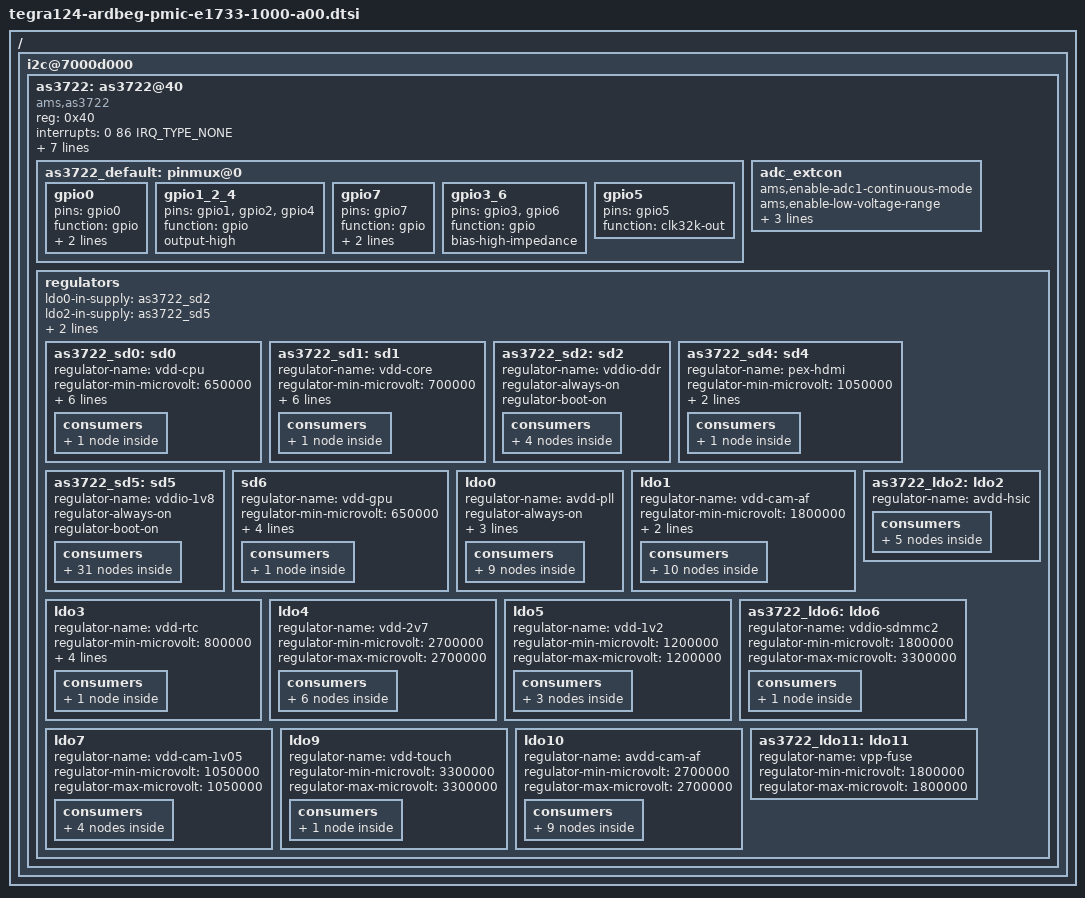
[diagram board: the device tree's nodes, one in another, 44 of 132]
/*
 * arch/arm/boot/dts/tegra124-platforms/tegra124-ardbeg-pmic-e1733-1000-a00.dtsi
 *
 * Copyright (c) 2014, NVIDIA CORPORATION.  All rights reserved.
 *
 * This program is free software; you can redistribute it and/or modify
 * it under the terms of the GNU General Public License as published by
 * the Free Software Foundation; either version 2 of the License, or
 * (at your option) any later version.
 *
 * This program is distributed in the hope that it will be useful, but WITHOUT
 * ANY WARRANTY; without even the implied warranty of MERCHANTABILITY or
 * FITNESS FOR A PARTICULAR PURPOSE.  See the GNU General Public License for
 * more details.
 *
 * You should have received a copy of the GNU General Public License along
 * with this program; if not, write to the Free Software Foundation, Inc.,
 * 51 Franklin Street, Fifth Floor, Boston, MA  02110-1301, USA.
 */

 #include <dt-bindings/gpio/tegra-gpio.h>
 #include <dt-bindings/mfd/as3722.h>
 #include <dt-bindings/regulator/regulator.h>

/ {
	i2c@7000d000 {
		as3722: as3722@40 {
			compatible = "ams,as3722";
			reg = <0x40>;
			interrupts = <0 86 IRQ_TYPE_NONE>;

			#interrupt-cells = <2>;
			interrupt-controller;

			gpio-controller;
			#gpio-cells = <2>;

			ams,major-rev = <1>;
			ams,minor-rev = <2>;
			ams,system-power-controller;
			ams,enable-clock32k-out;

			pinctrl-names = "default";
			pinctrl-0 = <&as3722_default>;

			as3722_default: pinmux@0 {
				gpio0 {
					pins = "gpio0";
					function = "gpio";
					bias-pull-down;
					output-low;
				};

				gpio1_2_4 {
					pins = "gpio1", "gpio2", "gpio4";
					function = "gpio";
					output-high;
				};

				gpio7 {
					pins = "gpio7";
					function = "gpio";
					bias-pull-up;
					output-low;
				};

				gpio3_6 {
					pins = "gpio3", "gpio6";
					function = "gpio";
					bias-high-impedance;
				};

				gpio5 {
					pins = "gpio5";
					function = "clk32k-out";
				};
			};

			adc_extcon: adc_extcon {
				ams,enable-adc1-continuous-mode;
				ams,enable-low-voltage-range;
				ams,adc-channel = <12>;
				ams,hi-threshold = <0x100>;
				ams,low-threshold = <0x80>;
				#extcon-cells = <1>;
				#io-channel-cells = <1>;
			};

			regulators {
				ldo0-in-supply = <&as3722_sd2>;
				ldo2-in-supply = <&as3722_sd5>;
				ldo5-in-supply = <&as3722_sd5>;
				ldo7-in-supply = <&as3722_sd5>;

				as3722_sd0: sd0 {
					regulator-name = "vdd-cpu";
					regulator-min-microvolt = <650000>;
					regulator-max-microvolt = <1400000>;
					regulator-max-microamp = <3500000>;
					regulator-always-on;
					regulator-boot-on;
					ams,ext-control = <AS3722_EXT_CONTROL_PIN_ENABLE2>;
					consumers {
						c1 {
							regulator-consumer-supply = "vdd_cpu";
						};
					};
				};

				as3722_sd1: sd1 {
					regulator-name = "vdd-core";
					regulator-min-microvolt = <700000>;
					regulator-max-microvolt = <1400000>;
					regulator-max-microamp = <3500000>;
					regulator-always-on;
					regulator-boot-on;
					ams,ext-control = <AS3722_EXT_CONTROL_PIN_ENABLE1>;

					consumers {
						c0 {
							regulator-consumer-supply = "vdd_core";
						};
					};
				};

				as3722_sd2: sd2 {
					regulator-name = "vddio-ddr";
					regulator-always-on;
					regulator-boot-on;

					consumers {
						c0 {
							regulator-consumer-supply = "vddio_ddr";
						};
						c1 {
							regulator-consumer-supply = "vddio_ddr_mclk";
						};
						c2 {
							regulator-consumer-supply = "vddio_ddr3";
						};
						c3 {
							regulator-consumer-supply = "vcore1_ddr3";
						};
					};
				};

				as3722_sd4: sd4 {
					regulator-name = "pex-hdmi";
					regulator-min-microvolt = <1050000>;
				        regulator-max-microvolt = <1050000>;
					regulator-boot-on;

					consumers {
						c6 {
							regulator-consumer-supply = "vddio_pex_sata";
							regulator-consumer-device = "tegra-sata.0";
						};
					};
				};

				as3722_sd5: sd5 {
					regulator-name = "vddio-1v8";
					regulator-always-on;
					regulator-boot-on;

					consumers {
						c0 {
							regulator-consumer-supply = "dbvdd";
							regulator-consumer-device = "tegra-snd-rt5639.0";
						};
						c1 {
							regulator-consumer-supply = "dbvdd";
							regulator-consumer-device = "tegra-snd-rt5645.0";
						};
						c2 {
							regulator-consumer-supply = "avdd";
							regulator-consumer-device = "tegra-snd-rt5639.0";
						};
						c3 {
							regulator-consumer-supply = "avdd";
							regulator-consumer-device = "tegra-snd-rt5645.0";
						};
						c4 {
							regulator-consumer-supply = "dmicvdd";
							regulator-consumer-device = "tegra-snd-rt5639.0";
						};
						c5 {
							regulator-consumer-supply = "dmicvdd";
							regulator-consumer-device = "tegra-snd-rt5645.0";
						};
						c6 {
							regulator-consumer-supply = "avdd_osc";
						};
						c7 {
							regulator-consumer-supply = "vddio_sys";
						};
						c8 {
							regulator-consumer-supply = "vddio_sys_2";
						};
						c9 {
							regulator-consumer-supply = "vddio_gmi";
						};
						c11 {
							regulator-consumer-supply = "vddio_sdmmc";
							regulator-consumer-device = "sdhci-tegra.0";
						};
						c13 {
							regulator-consumer-supply = "vddio_sdmmc";
							regulator-consumer-device = "sdhci-tegra.3";
						};
						c15 {
							regulator-consumer-supply = "avdd_pll_utmip";
							regulator-consumer-device = "tegra-udc.0";
						};
						c16 {
							regulator-consumer-supply = "avdd_pll_utmip";
							regulator-consumer-device = "tegra-ehci.0";
						};
						c17 {
							regulator-consumer-supply = "avdd_pll_utmip";
							regulator-consumer-device = "tegra-ehci.1";
						};
						c18 {
							regulator-consumer-supply = "avdd_pll_utmip";
							regulator-consumer-device = "tegra-ehci.2";
						};
						c20 {
							regulator-consumer-supply = "vddio_audio";
						};
						c22 {
							regulator-consumer-supply = "vddio_uart";
						};
						c24 {
							regulator-consumer-supply = "vddio_bb";
						};
						c26 {
							regulator-consumer-supply = "vdd_1v8b";
							regulator-consumer-device = "0-0048";
						};
						c27 {
							regulator-consumer-supply = "vdd_dtv";
						};
						c28 {
							regulator-consumer-supply = "vdd_1v8_eeprom";
						};
						c29 {
							regulator-consumer-supply = "vddio_cam";
							regulator-consumer-device = "tegra_camera";
						};
						c30 {
							regulator-consumer-supply = "vddio_cam";
							regulator-consumer-device = "vi";
						};
						c32 {
							regulator-consumer-supply = "dvdd";
							regulator-consumer-device = "spi0.0";
						};
						c33 {
							regulator-consumer-supply = "vlogic";
							regulator-consumer-device = "0-0069";
						};
						c34 {
							regulator-consumer-supply = "vid";
							regulator-consumer-device = "0-000c";
						};
						c35 {
							regulator-consumer-supply = "vddio";
							regulator-consumer-device = "0-0077";
						};
						c36 {
							regulator-consumer-supply = "vdd_sata";
							regulator-consumer-device = "tegra-sata.0";
						};
						c37 {
							regulator-consumer-supply = "avdd_sata";
							regulator-consumer-device = "tegra-sata.0";
						};
						c38 {
							regulator-consumer-supply = "avdd_sata_pll";
							regulator-consumer-device = "tegra-sata.0";
						};
					};
				};

				sd6 {
					regulator-name = "vdd-gpu";
					regulator-min-microvolt = <650000>;
					regulator-max-microvolt = <1400000>;
					regulator-init-microvolt = <900000>;
					regulator-max-microamp = <3500000>;
					regulator-boot-on;

					consumers {
						c0 {
							regulator-consumer-supply = "vdd_gpu";
						};
					};
				};

				ldo0 {
					regulator-name = "avdd-pll";
					regulator-always-on;
					regulator-boot-on;
					ams,ext-control = <AS3722_EXT_CONTROL_PIN_ENABLE1>;

					consumers {
						c0 {
							regulator-consumer-supply = "avdd_pll_m";
						};
						c1 {
							regulator-consumer-supply = "avdd_pll_ap_c2_c3";
						};
						c2 {
							regulator-consumer-supply = "avdd_pll_cud2dpd";
						};
						c3 {
							regulator-consumer-supply = "avdd_pll_c4";
						};
						c4 {
							regulator-consumer-supply = "avdd_lvds0_io";
						};
						c5 {
							regulator-consumer-supply = "vddio_ddr_hs";
						};
						c6 {
							regulator-consumer-supply = "avdd_pll_erefe";
						};
						c7 {
							regulator-consumer-supply = "avdd_pll_x";
						};
						c8 {
							regulator-consumer-supply = "avdd_pll_cg";
						};
					};
				};

				ldo1 {
					regulator-name = "vdd-cam-af";
					regulator-min-microvolt = <1800000>;
					regulator-max-microvolt = <1800000>;
					regulator-boot-on;

					consumers {
						c0 {
							regulator-consumer-supply = "vdd_cam1_1v8_cam";
						};
						c1 {
							regulator-consumer-supply = "vdd_cam2_1v8_cam";
						};
						c2 {
							regulator-consumer-supply = "vif";
							regulator-consumer-device = "2-0010";
						};
						c3 {
							regulator-consumer-supply = "vif";
							regulator-consumer-device = "2-0036";
						};
						c4 {
							regulator-consumer-supply = "vdd_i2c";
							regulator-consumer-device = "2-000c";
						};
						c5 {
							regulator-consumer-supply = "vi2c";
							regulator-consumer-device = "2-0030";
						};
						c6 {
							regulator-consumer-supply = "vif2";
							regulator-consumer-device = "2-0021";
						};
						c7 {
							regulator-consumer-supply = "dovdd";
							regulator-consumer-device = "2-0010";
						};
						c8 {
							regulator-consumer-supply = "vdd";
							regulator-consumer-device = "2-004a";
						};
						c9 {
							regulator-consumer-supply = "vif";
							regulator-consumer-device = "2-0048";
						};
					};
				};

				as3722_ldo2: ldo2 {
					regulator-name = "avdd-hsic";

					consumers {
						c0 {
							regulator-consumer-supply = "vddio_hsic";
							regulator-consumer-device = "tegra-ehci.1";
						};
						c1 {
							regulator-consumer-supply = "vddio_hsic";
							regulator-consumer-device = "tegra-ehci.2";
						};
						c6 {
							regulator-consumer-supply = "avdd_dsi_csi";
							regulator-consumer-device = "vi.1";
						};
						c8 {
							regulator-consumer-supply = "avdd_hsic_com";
						};
						c9 {
							regulator-consumer-supply = "avdd_hsic_mdm";
						};
					};
				};

				ldo3 {
					regulator-name = "vdd-rtc";
					regulator-min-microvolt = <800000>;
					regulator-max-microvolt = <800000>;
					regulator-always-on;
					regulator-boot-on;
					ams,enable-tracking;

					consumers {
						c0 {
							regulator-consumer-supply = "vdd_rtc";
						};
					};
				};

				ldo4 {
					regulator-name = "vdd-2v7";
					regulator-min-microvolt = <2700000>;
					regulator-max-microvolt = <2700000>;

					consumers {
						c0 {
							regulator-consumer-supply = "vdd_2v7_hv";
						};
						c1 {
							regulator-consumer-supply = "avdd_cam1_cam";
						};
						c2 {
							regulator-consumer-supply = "avdd_cam2_cam";
						};
						c3 {
							regulator-consumer-supply = "avdd_cam3_cam";
						};
						c4 {
							regulator-consumer-supply = "vana";
							regulator-consumer-device = "2-0010";
						};
						c5 {
							regulator-consumer-supply = "avdd_ov5693";
							regulator-consumer-device = "2-0010";
						};
					};
				};

				ldo5 {
					regulator-name = "vdd-1v2";
					regulator-min-microvolt = <1200000>;
					regulator-max-microvolt = <1200000>;

					consumers {
						c0 {
							regulator-consumer-supply = "vdd_1v2_cam";
						};
						c1 {
							regulator-consumer-supply = "vdig";
							regulator-consumer-device = "2-0010";
						};
						c2 {
							regulator-consumer-supply = "vdig";
							regulator-consumer-device = "2-0036";
						};
					};
				};

				as3722_ldo6: ldo6 {
					regulator-name = "vddio-sdmmc2";
					regulator-min-microvolt = <1800000>;
					regulator-max-microvolt = <3300000>;

					consumers {
						c0 {
							regulator-consumer-supply = "vddio_sdmmc";
							regulator-consumer-device = "sdhci-tegra.2";
						};
					};
				};

				ldo7 {
					regulator-name = "vdd-cam-1v05";
					regulator-min-microvolt = <1050000>;
					regulator-max-microvolt = <1050000>;

					consumers {
						c0 {
							regulator-consumer-supply = "vdd_cam_1v1_cam";
						};
						c1 {
							regulator-consumer-supply = "imx135_reg2";
						};
						c2 {
							regulator-consumer-supply = "vdig_lv";
							regulator-consumer-device = "2-0010";
						};
						c3 {
							regulator-consumer-supply = "dvdd";
							regulator-consumer-device = "2-0010";
						};
					};
				};

				ldo9 {
					regulator-name = "vdd-touch";
					regulator-min-microvolt = <3300000>;
					regulator-max-microvolt = <3300000>;

					consumers {
						c0 {
							regulator-consumer-supply = "avdd";
							regulator-consumer-device = "spi0.0";
						};
					};
				};

				ldo10 {
					regulator-name = "avdd-cam-af";
					regulator-min-microvolt = <2700000>;
					regulator-max-microvolt = <2700000>;

					consumers {
						c0 {
							regulator-consumer-supply = "avdd_af1_cam";
						};
						c1 {
							regulator-consumer-supply = "imx135_reg1";
						};
						c2 {
							regulator-consumer-supply = "vdd";
							regulator-consumer-device = "2-000c";
						};
						c3 {
							regulator-consumer-supply = "vin";
							regulator-consumer-device = "2-0030";
						};
						c4 {
							regulator-consumer-supply = "vana";
							regulator-consumer-device = "2-0036";
						};
						c5 {
							regulator-consumer-supply = "vana";
							regulator-consumer-device = "2-0021";
						};
						c6 {
							regulator-consumer-supply = "vdd_af1";
							regulator-consumer-device = "2-0010";
						};
						c7 {
							regulator-consumer-supply = "vin";
							regulator-consumer-device = "2-004a";
						};
						c8 {
							regulator-consumer-supply = "vana";
							regulator-consumer-device = "2-0048";
						};
					};
				};

				as3722_ldo11: ldo11 {
					regulator-name = "vpp-fuse";
					regulator-min-microvolt = <1800000>;
					regulator-max-microvolt = <1800000>;
				};
			};
		};
	};
};
